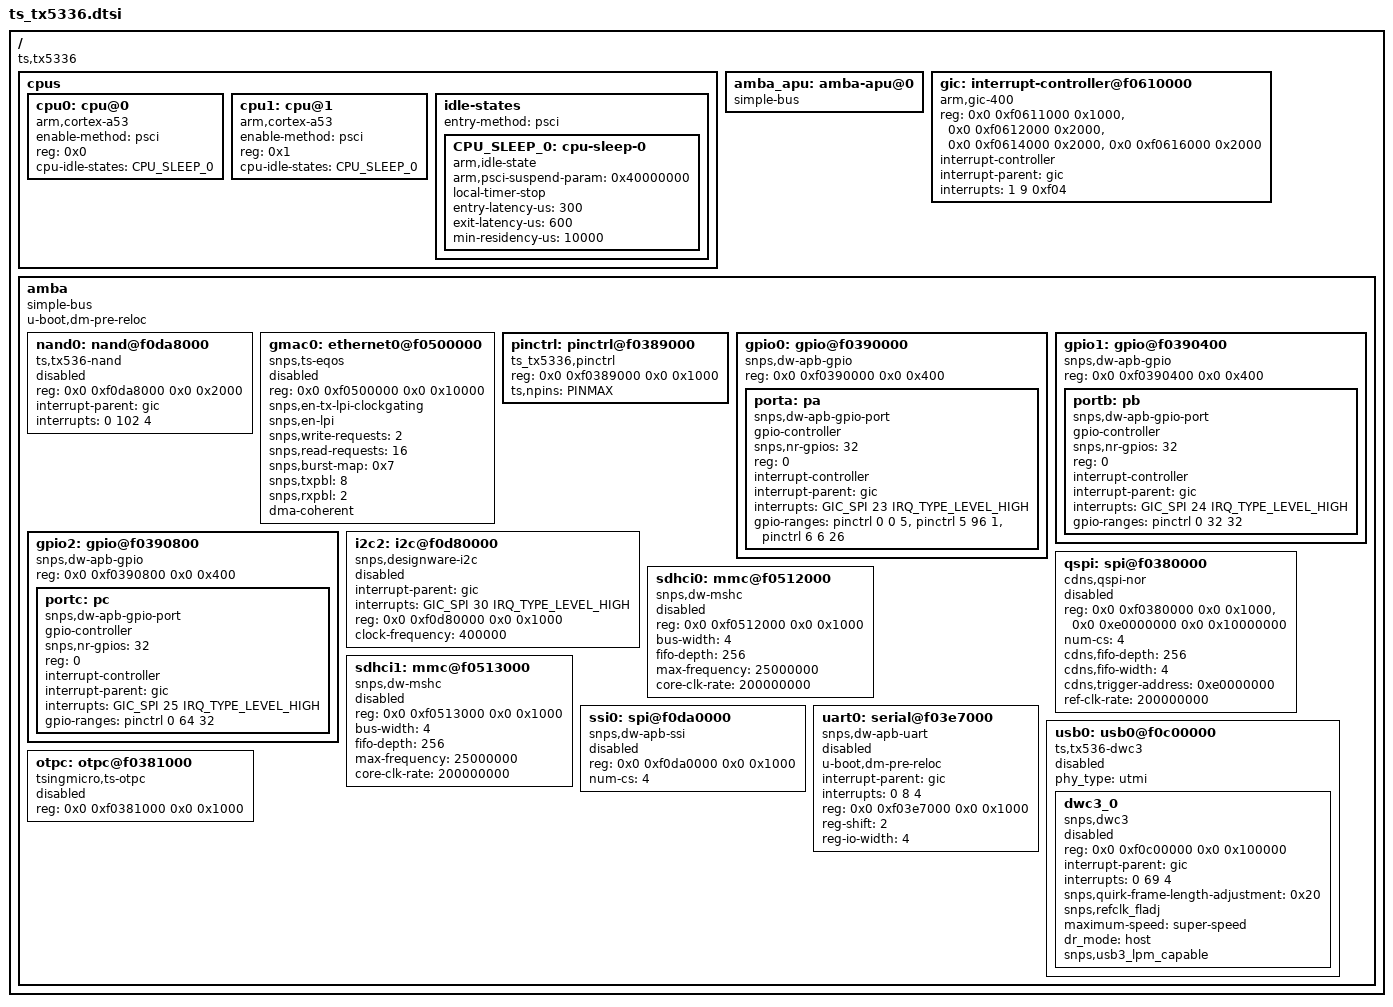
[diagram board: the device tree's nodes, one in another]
// SPDX-License-Identifier: GPL-2.0+
/*
 * dts file for tsingmicro tx5336
 *
 * Copyright 2022 Beijing Tsingmicro Intelligent Technology Co.,Ltd.
 *
 */

#include <dt-bindings/gpio/gpio.h>
#include <dt-bindings/interrupt-controller/irq.h>
#include <dt-bindings/interrupt-controller/arm-gic.h>
#include <dt-bindings/pinctrl/pinctrl-ts-tx5336.h>

/ {
	compatible = "ts,tx5336";
	#address-cells = <2>;
	#size-cells = <2>;

	cpus {
		#address-cells = <1>;
		#size-cells = <0>;

		cpu0: cpu@0 {
			compatible = "arm,cortex-a53";
			device_type = "cpu";
			enable-method = "psci";
			// operating-points-v2 = <&cpu_opp_table>;		/* TODO */
			reg = <0x0>;
			cpu-idle-states = <&CPU_SLEEP_0>;
		};

		cpu1: cpu@1 {
			compatible = "arm,cortex-a53";
			device_type = "cpu";
			enable-method = "psci";
			reg = <0x1>;
			// operating-points-v2 = <&cpu_opp_table>;
			cpu-idle-states = <&CPU_SLEEP_0>;
		};

		idle-states {
			entry-method = "psci";

			CPU_SLEEP_0: cpu-sleep-0 {
				compatible = "arm,idle-state";
				arm,psci-suspend-param = <0x40000000>;
				local-timer-stop;
				entry-latency-us = <300>;
				exit-latency-us = <600>;
				min-residency-us = <10000>;
			};
		};
	};

	/* not use */
	amba_apu: amba-apu@0 {
		compatible = "simple-bus";
		#address-cells = <2>;
		#size-cells = <1>;
		ranges = <0 0 0 0 0xffffffff>;

	};

	gic: interrupt-controller@f0610000 {
		compatible = "arm,gic-400";
		#interrupt-cells = <3>;
		reg = <0x0 0xf0611000 0x1000>,
		      <0x0 0xf0612000 0x2000>,
		      <0x0 0xf0614000 0x2000>,
		      <0x0 0xf0616000 0x2000>;
		interrupt-controller;
		interrupt-parent = <&gic>;
		interrupts = <1 9 0xf04>;
	};

	amba: amba {
		compatible = "simple-bus";
		u-boot,dm-pre-reloc;
		#address-cells = <2>;
		#size-cells = <2>;
		ranges;

		nand0: nand@f0da8000 {
			compatible = "ts,tx536-nand";
			reg = <0x0 0xf0da8000 0x0 0x2000>;
			reg-names = "ts-nand";
			#address-cells = <1>;
			#size-cells = <1>;
			interrupt-parent = <&gic>;
			//interrupts = <GIC_SPI 102 IRQ_TYPE_LEVEL_HIGH>;
			interrupts = <0 102 4>;
			interrupt-names = "bch";
			//dmas = <&dma_apbh 0>;
			//dma-names = "rx-tx";
			#stream-id-cells = <1>;
			//iommus = <&smmu 0x872>;

			status = "disabled";
		};

		gmac0: ethernet0@f0500000 {
			compatible = "snps,ts-eqos";
			//local-mac-address = [ 00 18 fe 66 66 66 ];
			reg = <0x0 0xf0500000 0x0 0x10000>;
			#address-cells = <1>;
			#size-cells = <0>;
			snps,en-tx-lpi-clockgating;
			snps,en-lpi;
			snps,write-requests = <2>;
			snps,read-requests = <16>;
			snps,burst-map = <0x7>;
			snps,txpbl = <8>;
			snps,rxpbl = <2>;
			dma-coherent;
			status = "disable";
		};

		pinctrl: pinctrl@f0389000 {
			compatible = "ts_tx5336,pinctrl";
			reg = <0x0 0xf0389000 0x0 0x1000>;
			ts,npins = <PINMAX>;
		};

		gpio0: gpio@f0390000 {
			#address-cells = <1>;
			#size-cells = <0>;
			compatible = "snps,dw-apb-gpio";
			reg = <0x0 0xf0390000 0x0 0x400>;

			porta: pa {
				compatible = "snps,dw-apb-gpio-port";
				gpio-controller;
				#gpio-cells = <2>;
				snps,nr-gpios = <32>;
				reg = <0>;
				interrupt-controller;
				#interrupt-cells = <2>;
				interrupt-parent = <&gic>;
				interrupts = <GIC_SPI 23 IRQ_TYPE_LEVEL_HIGH>;
				gpio-ranges = <&pinctrl 0 0 5>,
							<&pinctrl 5 96 1>,
							<&pinctrl 6 6 26>;
			};
		};

		gpio1: gpio@f0390400 {
			#address-cells = <1>;
			#size-cells = <0>;
			compatible = "snps,dw-apb-gpio";
			reg = <0x0 0xf0390400 0x0 0x400>;

			portb: pb {
				compatible = "snps,dw-apb-gpio-port";
				gpio-controller;
				#gpio-cells = <2>;
				snps,nr-gpios = <32>;
				reg = <0>;
				interrupt-controller;
				#interrupt-cells = <2>;
				interrupt-parent = <&gic>;
				interrupts = <GIC_SPI 24 IRQ_TYPE_LEVEL_HIGH>;
				gpio-ranges = <&pinctrl 0 32 32>;
			};
		};

		gpio2: gpio@f0390800 {
			#address-cells = <1>;
			#size-cells = <0>;
			compatible = "snps,dw-apb-gpio";
			reg = <0x0 0xf0390800 0x0 0x400>;

			portc: pc {
				compatible = "snps,dw-apb-gpio-port";
				gpio-controller;
				#gpio-cells = <2>;
				snps,nr-gpios = <32>;
				reg = <0>;
				interrupt-controller;
				#interrupt-cells = <2>;
				interrupt-parent = <&gic>;
				interrupts = <GIC_SPI 25 IRQ_TYPE_LEVEL_HIGH>;
				gpio-ranges = <&pinctrl 0 64 32>;
			};
		};

		i2c2: i2c@f0d80000 {
			compatible = "snps,designware-i2c";
			status = "disabled";
			interrupt-parent = <&gic>;
			interrupts = <GIC_SPI 30 IRQ_TYPE_LEVEL_HIGH>;
			reg = <0x0 0xf0d80000 0x0 0x1000>;
			clock-frequency = <400000>;
			#address-cells = <1>;
			#size-cells = <0>;
		};

		qspi: spi@f0380000 {
			compatible =  "cdns,qspi-nor";
			status = "disabled";
			reg = <0x0 0xf0380000 0x0 0x1000>,
				<0x0 0xe0000000 0x0 0x10000000>;
			num-cs = <4>;
			cdns,fifo-depth = <256>;
			cdns,fifo-width = <4>;
			cdns,trigger-address = <0xe0000000>;
            ref-clk-rate = <200000000>;
			/*cdns,is-decoded-cs = <0>;*/
		};

		sdhci0: mmc@f0512000 {
			compatible = "snps,dw-mshc";
			status = "disabled";
			reg = <0x0 0xf0512000 0x0 0x1000>;
			bus-width = <4>;
			fifo-depth = <256>;
			max-frequency = <25000000>;
            core-clk-rate = <200000000>;
		};
        
		sdhci1: mmc@f0513000 {
			compatible = "snps,dw-mshc";
			status = "disabled";
			reg = <0x0 0xf0513000 0x0 0x1000>;
			bus-width = <4>;
			fifo-depth = <256>;
			max-frequency = <25000000>;
            core-clk-rate = <200000000>;
		};

		ssi0: spi@f0da0000 {
			compatible = "snps,dw-apb-ssi";
			status = "disabled";
			reg = <0x0 0xf0da0000 0x0 0x1000>;
			num-cs = <4>;
		};

		uart0: serial@f03e7000 {
			u-boot,dm-pre-reloc;
			compatible = "snps,dw-apb-uart";
			status = "disabled";
			interrupt-parent = <&gic>;
			interrupts = <0 8 4>;
			reg = <0x0 0xf03e7000 0x0 0x1000>;
			clock-names = "uart_clk", "pclk";
			reg-shift = <2>;
			reg-io-width = <4>;
		};

		usb0: usb0@f0c00000 {
			#address-cells = <2>;
			#size-cells = <2>;
			status = "disabled";
			compatible = "ts,tx536-dwc3";
			phy_type = "utmi";

			dwc3_0: dwc3_0 {
				compatible = "snps,dwc3";
				status = "disabled";
				reg = <0x0 0xf0c00000 0x0 0x100000>;
				interrupt-parent = <&gic>;
				interrupts = <0 69 4>;
				#stream-id-cells = <1>;
				/*iommus = <&smmu 0x860>;*/
				snps,quirk-frame-length-adjustment = <0x20>;
				snps,refclk_fladj;
				/* dma-coherent; */
				maximum-speed = "super-speed";
				dr_mode = "host";
				/*dr_mode = "peripheral";*/
				snps,usb3_lpm_capable;
			};
		};

		otpc: otpc@f0381000 {
			compatible = "tsingmicro,ts-otpc";
			status = "disabled";
			reg = <0x0 0xf0381000 0x0 0x1000>;
		};
	};
};
